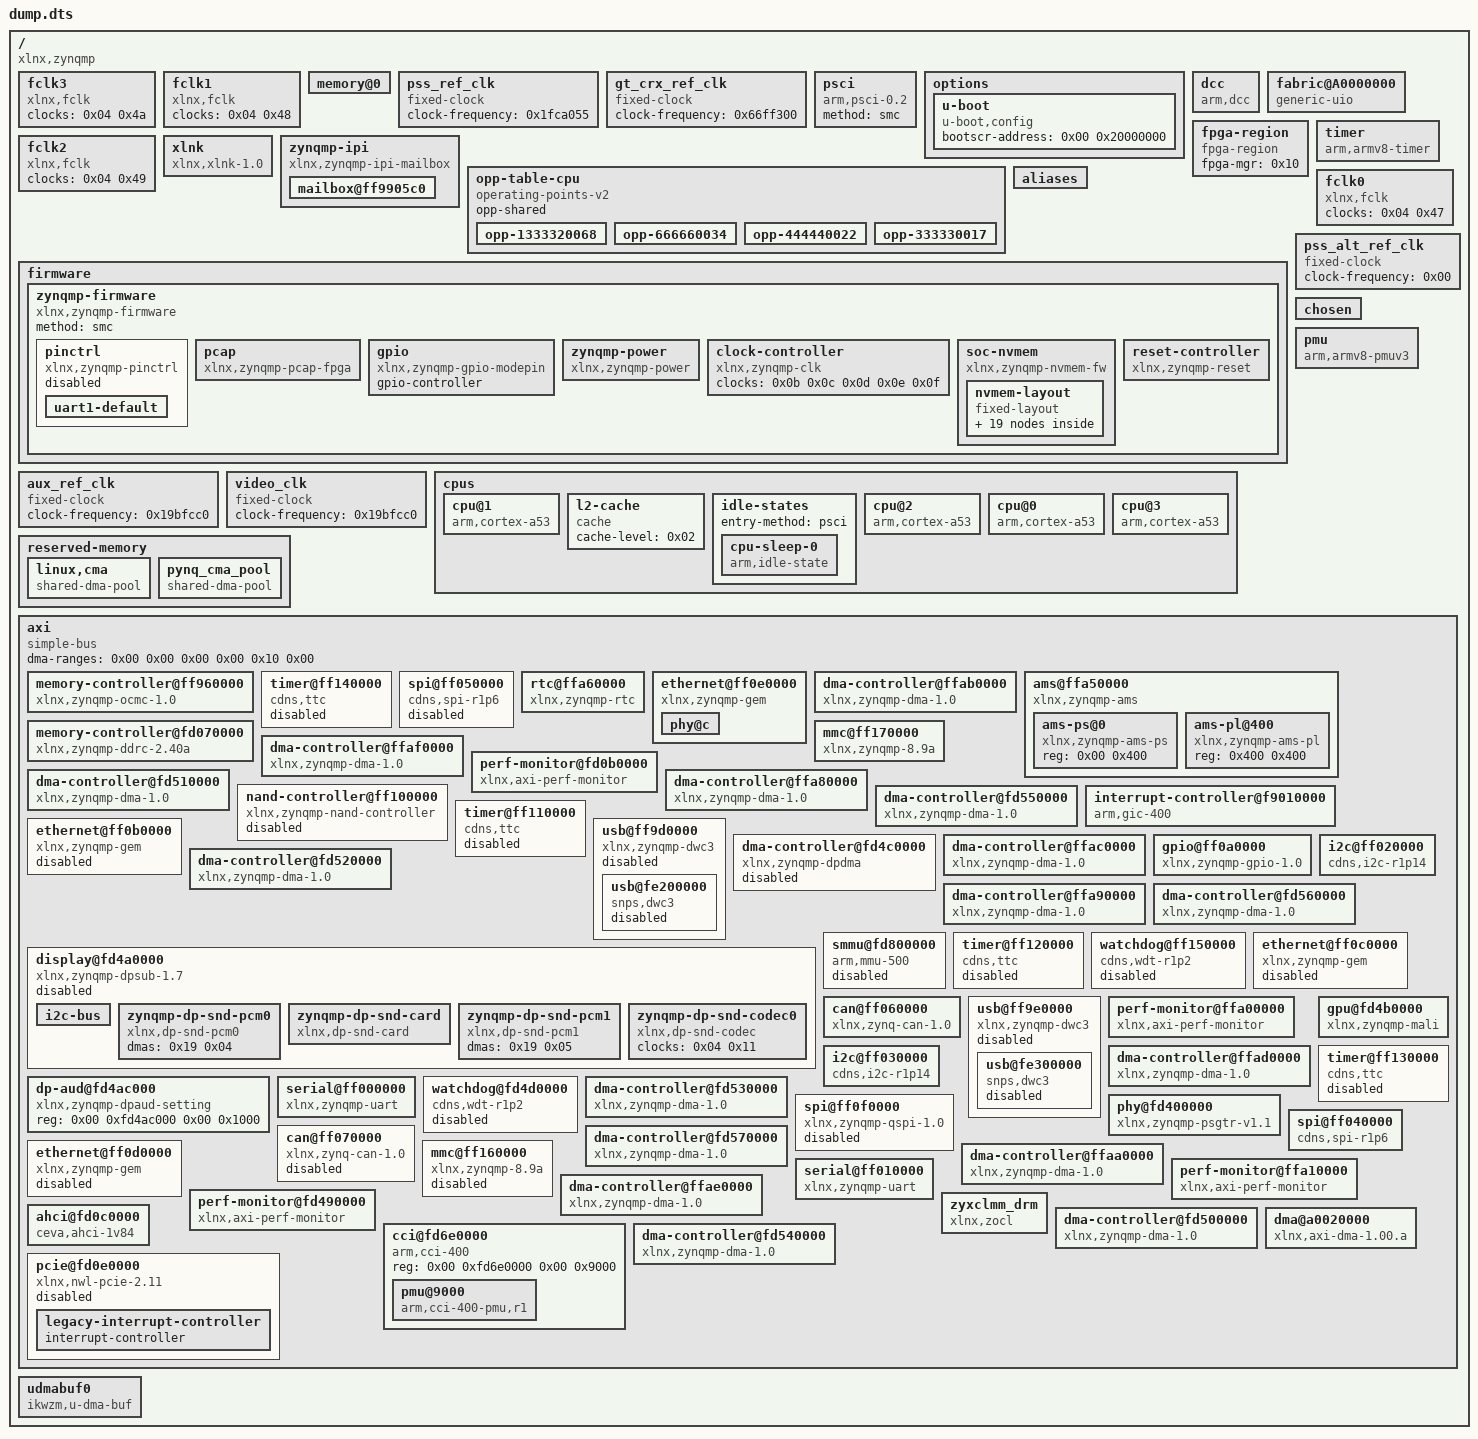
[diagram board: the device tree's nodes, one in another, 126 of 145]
/dts-v1/;

/ {
	#address-cells = <0x02>;
	#size-cells = <0x02>;
	compatible = "xlnx,zynqmp";

	fclk3 {
		clock-names = "fclk3";
		clocks = <0x04 0x4a>;
		compatible = "xlnx,fclk";
		status = "okay";
		phandle = <0x76>;
	};

	fclk1 {
		clock-names = "fclk1";
		clocks = <0x04 0x48>;
		compatible = "xlnx,fclk";
		status = "okay";
		phandle = <0x74>;
	};

	memory@0 {
		device_type = "memory";
		reg = <0x00 0x00 0x00 0x7ff00000 0x08 0x00 0x03 0x80000000>;
	};

	pss_ref_clk {
		bootph-all;
		#clock-cells = <0x00>;
		clock-frequency = <0x1fca055>;
		compatible = "fixed-clock";
		phandle = <0x0b>;
	};

	gt_crx_ref_clk {
		bootph-all;
		#clock-cells = <0x00>;
		clock-frequency = <0x66ff300>;
		compatible = "fixed-clock";
		phandle = <0x0f>;
	};

	psci {
		method = "smc";
		compatible = "arm,psci-0.2";
	};

	options {

		u-boot {
			compatible = "u-boot,config";
			bootscr-address = <0x00 0x20000000>;
		};
	};

	dcc {
		bootph-all;
		compatible = "arm,dcc";
		status = "okay";
		phandle = <0x20>;
	};

	fragment@0 {
		target-path = "/axi";

		__overlay__ {
			#address-cells = <0x02>;
			#size-cells = <0x01>;

			dma@a0020000 {
				dma-coherent;
				compatible = "xlnx,axi-dma-1.00.a";
				status = "okay";
				reg = <0x00 0xa0020000 0x10000>;
				phandle = <0x79>;
			};
		};
	};

	fabric@A0000000 {
		interrupts = <0x00 0x59 0x04>;
		interrupt-parent = <0x05>;
		compatible = "generic-uio";
		reg = <0x00 0xa0000000 0x00 0x10000>;
	};

	fpga-region {
		fpga-mgr = <0x10>;
		#address-cells = <0x02>;
		#size-cells = <0x02>;
		compatible = "fpga-region";
		ranges;
		phandle = <0x36>;
	};

	timer {
		interrupts = <0x01 0x0d 0xf08 0x01 0x0e 0xf08 0x01 0x0b 0xf08 0x01 0x0a 0xf08>;
		interrupt-parent = <0x05>;
		compatible = "arm,armv8-timer";
	};

	fclk2 {
		clock-names = "fclk2";
		clocks = <0x04 0x49>;
		compatible = "xlnx,fclk";
		status = "okay";
		phandle = <0x75>;
	};

	xlnk {
		compatible = "xlnx,xlnk-1.0";
	};

	zynqmp-ipi {
		#address-cells = <0x02>;
		xlnx,ipi-id = <0x00>;
		bootph-all;
		interrupts = <0x00 0x23 0x04>;
		#size-cells = <0x02>;
		interrupt-parent = <0x05>;
		compatible = "xlnx,zynqmp-ipi-mailbox";
		ranges;
		phandle = <0x1f>;

		mailbox@ff9905c0 {
			xlnx,ipi-id = <0x04>;
			reg-names = "local_request_region\0local_response_region\0remote_request_region\0remote_response_region";
			bootph-all;
			#mbox-cells = <0x01>;
			reg = <0x00 0xff9905c0 0x00 0x20 0x00 0xff9905e0 0x00 0x20 0x00 0xff990e80 0x00 0x20 0x00 0xff990ea0 0x00 0x20>;
			phandle = <0x0a>;
		};
	};

	opp-table-cpu {
		opp-shared;
		compatible = "operating-points-v2";
		phandle = <0x01>;

		opp-1333320068 {
			opp-microvolt = <0xf4240>;
			opp-hz = <0x00 0x4f78d984>;
			clock-latency-ns = <0x7a120>;
		};

		opp-666660034 {
			opp-microvolt = <0xf4240>;
			opp-hz = <0x00 0x27bc6cc2>;
			clock-latency-ns = <0x7a120>;
		};

		opp-444440022 {
			opp-microvolt = <0xf4240>;
			opp-hz = <0x00 0x1a7d9dd6>;
			clock-latency-ns = <0x7a120>;
		};

		opp-333330017 {
			opp-microvolt = <0xf4240>;
			opp-hz = <0x00 0x13de3661>;
			clock-latency-ns = <0x7a120>;
		};
	};

	aliases {
		ethernet0 = "/axi/ethernet@ff0e0000";
		i2c1 = "/axi/i2c@ff030000";
		spi0 = "/axi/spi@ff040000";
		serial1 = "/dcc";
		i2c0 = "/axi/i2c@ff020000";
		serial2 = "/axi/serial@ff010000";
		serial0 = "/axi/serial@ff000000";
	};

	firmware {

		zynqmp-firmware {
			method = "smc";
			bootph-all;
			#power-domain-cells = <0x01>;
			compatible = "xlnx,zynqmp-firmware";
			phandle = <0x12>;

			pinctrl {
				compatible = "xlnx,zynqmp-pinctrl";
				status = "disabled";
				phandle = <0x35>;

				uart1-default {
				};
			};

			pcap {
				compatible = "xlnx,zynqmp-pcap-fpga";
				phandle = <0x10>;
			};

			gpio {
				gpio-controller;
				compatible = "xlnx,zynqmp-gpio-modepin";
				phandle = <0x17>;
				#gpio-cells = <0x02>;
			};

			zynqmp-power {
				bootph-all;
				interrupts = <0x00 0x23 0x04>;
				interrupt-parent = <0x05>;
				compatible = "xlnx,zynqmp-power";
				phandle = <0x21>;
				mboxes = <0x0a 0x00 0x0a 0x01>;
				mbox-names = "tx\0rx";
			};

			clock-controller {
				clock-names = "pss_ref_clk\0video_clk\0pss_alt_ref_clk\0aux_ref_clk\0gt_crx_ref_clk";
				bootph-all;
				clocks = <0x0b 0x0c 0x0d 0x0e 0x0f>;
				#clock-cells = <0x01>;
				compatible = "xlnx,zynqmp-clk";
				phandle = <0x04>;
			};

			soc-nvmem {
				compatible = "xlnx,zynqmp-nvmem-fw";

				nvmem-layout {
					#address-cells = <0x01>;
					#size-cells = <0x01>;
					compatible = "fixed-layout";

					efuse-usr3@2c {
						reg = <0x2c 0x04>;
						phandle = <0x27>;
					};

					efuse-pufuser@100 {
						reg = <0x100 0x7f>;
						phandle = <0x34>;
					};

					efuse-ppk1hash@d0 {
						reg = <0xd0 0x30>;
						phandle = <0x33>;
					};

					efuse-sec@58 {
						reg = <0x58 0x04>;
						phandle = <0x2f>;
					};

					efuse-ppk0hash@a0 {
						reg = <0xa0 0x30>;
						phandle = <0x32>;
					};

					efuse-usr1@24 {
						reg = <0x24 0x04>;
						phandle = <0x25>;
					};

					efuse-miscusr@40 {
						reg = <0x40 0x04>;
						phandle = <0x2c>;
					};

					efuse-usr6@38 {
						reg = <0x38 0x04>;
						phandle = <0x2a>;
					};

					efuse-usr4@30 {
						reg = <0x30 0x04>;
						phandle = <0x28>;
					};

					efuse-dna@c {
						reg = <0x0c 0x0c>;
						phandle = <0x23>;
					};

					soc-revision@0 {
						reg = <0x00 0x04>;
						phandle = <0x22>;
					};

					efuse-spkid@5c {
						reg = <0x5c 0x04>;
						phandle = <0x30>;
					};

					efuse-chash@50 {
						reg = <0x50 0x04>;
						phandle = <0x2d>;
					};

					efuse-pufmisc@54 {
						reg = <0x54 0x04>;
						phandle = <0x2e>;
					};

					efuse-usr7@3c {
						reg = <0x3c 0x04>;
						phandle = <0x2b>;
					};

					efuse-usr2@28 {
						reg = <0x28 0x04>;
						phandle = <0x26>;
					};

					efuse-usr0@20 {
						reg = <0x20 0x04>;
						phandle = <0x24>;
					};

					efuse-aeskey@60 {
						reg = <0x60 0x20>;
						phandle = <0x31>;
					};

					efuse-usr5@34 {
						reg = <0x34 0x04>;
						phandle = <0x29>;
					};
				};
			};

			reset-controller {
				#reset-cells = <0x01>;
				compatible = "xlnx,zynqmp-reset";
				phandle = <0x11>;
			};
		};
	};

	fclk0 {
		clock-names = "fclk0";
		clocks = <0x04 0x47>;
		compatible = "xlnx,fclk";
		status = "okay";
		phandle = <0x73>;
	};

	pss_alt_ref_clk {
		bootph-all;
		#clock-cells = <0x00>;
		clock-frequency = <0x00>;
		compatible = "fixed-clock";
		phandle = <0x0d>;
	};

	aux_ref_clk {
		bootph-all;
		#clock-cells = <0x00>;
		clock-frequency = <0x19bfcc0>;
		compatible = "fixed-clock";
		phandle = <0x0e>;
	};

	chosen {
		u-boot,version = "2024.01";
		bootargs = "root=/dev/mmcblk0p2 rw earlyprintk rootfstype=ext4 rootwait devtmpfs.mount=1 uio_pdrv_genirq.of_id=\"generic-uio\" clk_ignore_unused";
		u-boot,bootconf = "conf-1";
		pynq_board = "Pynq-IMPCAS-ZU15";
		stdout-path = "serial0:115200n8";
	};

	video_clk {
		bootph-all;
		#clock-cells = <0x00>;
		clock-frequency = <0x19bfcc0>;
		compatible = "fixed-clock";
		phandle = <0x0c>;
	};

	pmu {
		interrupt-affinity = <0x06 0x07 0x08 0x09>;
		interrupts = <0x00 0x8f 0x04 0x00 0x90 0x04 0x00 0x91 0x04 0x00 0x92 0x04>;
		interrupt-parent = <0x05>;
		compatible = "arm,armv8-pmuv3";
	};

	cpus {
		#address-cells = <0x01>;
		#size-cells = <0x00>;

		cpu@1 {
			cpu-idle-states = <0x02>;
			device_type = "cpu";
			compatible = "arm,cortex-a53";
			next-level-cache = <0x03>;
			reg = <0x01>;
			enable-method = "psci";
			phandle = <0x07>;
			operating-points-v2 = <0x01>;
		};

		l2-cache {
			cache-level = <0x02>;
			compatible = "cache";
			phandle = <0x03>;
		};

		idle-states {
			entry-method = "psci";

			cpu-sleep-0 {
				entry-latency-us = <0x12c>;
				local-timer-stop;
				exit-latency-us = <0x258>;
				arm,psci-suspend-param = <0x40000000>;
				compatible = "arm,idle-state";
				phandle = <0x02>;
				min-residency-us = <0x2710>;
			};
		};

		cpu@2 {
			cpu-idle-states = <0x02>;
			device_type = "cpu";
			compatible = "arm,cortex-a53";
			next-level-cache = <0x03>;
			reg = <0x02>;
			enable-method = "psci";
			phandle = <0x08>;
			operating-points-v2 = <0x01>;
		};

		cpu@0 {
			clocks = <0x04 0x0a>;
			cpu-idle-states = <0x02>;
			device_type = "cpu";
			compatible = "arm,cortex-a53";
			next-level-cache = <0x03>;
			reg = <0x00>;
			enable-method = "psci";
			phandle = <0x06>;
			operating-points-v2 = <0x01>;
		};

		cpu@3 {
			cpu-idle-states = <0x02>;
			device_type = "cpu";
			compatible = "arm,cortex-a53";
			next-level-cache = <0x03>;
			reg = <0x03>;
			enable-method = "psci";
			phandle = <0x09>;
			operating-points-v2 = <0x01>;
		};
	};

	__symbols__ {
		axi_dma_coherent = "/fragment@0/__overlay__/dma@a0020000";
		efuse_usr0 = "/firmware/zynqmp-firmware/soc-nvmem/nvmem-layout/efuse-usr0@20";
		fpd_dma_chan3 = "/axi/dma-controller@fd520000";
		efuse_ppk0hash = "/firmware/zynqmp-firmware/soc-nvmem/nvmem-layout/efuse-ppk0hash@a0";
		ams_ps = "/axi/ams@ffa50000/ams-ps@0";
		nand0 = "/axi/nand-controller@ff100000";
		fclk3 = "/fclk3";
		zynqmp_pcap = "/firmware/zynqmp-firmware/pcap";
		CPU_SLEEP_0 = "/cpus/idle-states/cpu-sleep-0";
		phyc = "/axi/ethernet@ff0e0000/phy@c";
		efuse_chash = "/firmware/zynqmp-firmware/soc-nvmem/nvmem-layout/efuse-chash@50";
		ipi_mailbox_pmu1 = "/zynqmp-ipi/mailbox@ff9905c0";
		i2c1 = "/axi/i2c@ff030000";
		fpd_dma_chan1 = "/axi/dma-controller@fd500000";
		efuse_sec = "/firmware/zynqmp-firmware/soc-nvmem/nvmem-layout/efuse-sec@58";
		ttc3 = "/axi/timer@ff140000";
		qspi = "/axi/spi@ff0f0000";
		zynqmp_dp_snd_pcm0 = "/axi/display@fd4a0000/zynqmp-dp-snd-pcm0";
		fclk1 = "/fclk1";
		gpu = "/axi/gpu@fd4b0000";
		spi0 = "/axi/spi@ff040000";
		lpd_dma_chan8 = "/axi/dma-controller@ffaf0000";
		efuse_usr7 = "/firmware/zynqmp-firmware/soc-nvmem/nvmem-layout/efuse-usr7@3c";
		gpio = "/axi/gpio@ff0a0000";
		zynqmp_clk = "/firmware/zynqmp-firmware/clock-controller";
		usb1 = "/axi/usb@ff9e0000";
		ttc1 = "/axi/timer@ff120000";
		amba = "/axi";
		efuse_spkid = "/firmware/zynqmp-firmware/soc-nvmem/nvmem-layout/efuse-spkid@5c";
		pss_ref_clk = "/pss_ref_clk";
		lpd_dma_chan6 = "/axi/dma-controller@ffad0000";
		efuse_usr5 = "/firmware/zynqmp-firmware/soc-nvmem/nvmem-layout/efuse-usr5@34";
		fpd_dma_chan8 = "/axi/dma-controller@fd570000";
		efuse_ppk1hash = "/firmware/zynqmp-firmware/soc-nvmem/nvmem-layout/efuse-ppk1hash@d0";
		gem3 = "/axi/ethernet@ff0e0000";
		cpu3 = "/cpus/cpu@3";
		zynqmp_dpaud_setting = "/axi/dp-aud@fd4ac000";
		dwc3_0 = "/axi/usb@ff9d0000/usb@fe200000";
		perf_monitor_cci = "/axi/perf-monitor@fd490000";
		lpd_dma_chan4 = "/axi/dma-controller@ffab0000";
		efuse_usr3 = "/firmware/zynqmp-firmware/soc-nvmem/nvmem-layout/efuse-usr3@2c";
		fpd_dma_chan6 = "/axi/dma-controller@fd550000";
		efuse_aeskey = "/firmware/zynqmp-firmware/soc-nvmem/nvmem-layout/efuse-aeskey@60";
		gt_crx_ref_clk = "/gt_crx_ref_clk";
		gic = "/axi/interrupt-controller@f9010000";
		gem1 = "/axi/ethernet@ff0c0000";
		sata = "/axi/ahci@fd0c0000";
		cpu1 = "/cpus/cpu@1";
		xilinx_ams = "/axi/ams@ffa50000";
		perf_monitor_lpd = "/axi/perf-monitor@ffa10000";
		uart0 = "/axi/serial@ff000000";
		zynqmp_dp_snd_codec0 = "/axi/display@fd4a0000/zynqmp-dp-snd-codec0";
		dcc = "/dcc";
		lpd_dma_chan2 = "/axi/dma-controller@ffa90000";
		ams_pl = "/axi/ams@ffa50000/ams-pl@400";
		L2 = "/cpus/l2-cache";
		efuse_usr1 = "/firmware/zynqmp-firmware/soc-nvmem/nvmem-layout/efuse-usr1@24";
		fpd_dma_chan4 = "/axi/dma-controller@fd530000";
		cci = "/axi/cci@fd6e0000";
		perf_monitor_ddr = "/axi/perf-monitor@fd0b0000";
		cpu_opp_table = "/opp-table-cpu";
		can0 = "/axi/can@ff060000";
		pcie = "/axi/pcie@fd0e0000";
		sdhci0 = "/axi/mmc@ff160000";
		perf_monitor_ocm = "/axi/perf-monitor@ffa00000";
		watchdog0 = "/axi/watchdog@fd4d0000";
		fpga_full = "/fpga-region";
		fpd_dma_chan2 = "/axi/dma-controller@fd510000";
		zynqmp_firmware = "/firmware/zynqmp-firmware";
		zynqmp_dp_snd_pcm1 = "/axi/display@fd4a0000/zynqmp-dp-snd-pcm1";
		fclk2 = "/fclk2";
		spi1 = "/axi/spi@ff050000";
		sys_cma = "/reserved-memory/linux,cma";
		ocm = "/axi/memory-controller@ff960000";
		i2c0 = "/axi/i2c@ff020000";
		ttc2 = "/axi/timer@ff130000";
		soc_revision = "/firmware/zynqmp-firmware/soc-nvmem/nvmem-layout/soc-revision@0";
		fclk0 = "/fclk0";
		pss_alt_ref_clk = "/pss_alt_ref_clk";
		lpd_dma_chan7 = "/axi/dma-controller@ffae0000";
		efuse_usr6 = "/firmware/zynqmp-firmware/soc-nvmem/nvmem-layout/efuse-usr6@38";
		efuse_dna = "/firmware/zynqmp-firmware/soc-nvmem/nvmem-layout/efuse-dna@c";
		aux_ref_clk = "/aux_ref_clk";
		psgtr = "/axi/phy@fd400000";
		usb0 = "/axi/usb@ff9d0000";
		ttc0 = "/axi/timer@ff110000";
		efuse_pufuser = "/firmware/zynqmp-firmware/soc-nvmem/nvmem-layout/efuse-pufuser@100";
		mc = "/axi/memory-controller@fd070000";
		zynqmp_dpsub = "/axi/display@fd4a0000";
		pinctrl0 = "/firmware/zynqmp-firmware/pinctrl";
		dwc3_1 = "/axi/usb@ff9e0000/usb@fe300000";
		lpd_dma_chan5 = "/axi/dma-controller@ffac0000";
		zynqmp_ipi = "/zynqmp-ipi";
		efuse_usr4 = "/firmware/zynqmp-firmware/soc-nvmem/nvmem-layout/efuse-usr4@30";
		fpd_dma_chan7 = "/axi/dma-controller@fd560000";
		video_clk = "/video_clk";
		gem2 = "/axi/ethernet@ff0d0000";
		efuse_pufmisc = "/firmware/zynqmp-firmware/soc-nvmem/nvmem-layout/efuse-pufmisc@54";
		zynqmp_dpdma = "/axi/dma-controller@fd4c0000";
		cpu2 = "/cpus/cpu@2";
		uart1 = "/axi/serial@ff010000";
		efuse_miscusr = "/firmware/zynqmp-firmware/soc-nvmem/nvmem-layout/efuse-miscusr@40";
		lpd_dma_chan3 = "/axi/dma-controller@ffaa0000";
		efuse_usr2 = "/firmware/zynqmp-firmware/soc-nvmem/nvmem-layout/efuse-usr2@28";
		fpd_dma_chan5 = "/axi/dma-controller@fd540000";
		zynqmp_dp_snd_card0 = "/axi/display@fd4a0000/zynqmp-dp-snd-card";
		zynqmp_power = "/firmware/zynqmp-firmware/zynqmp-power";
		can1 = "/axi/can@ff070000";
		gem0 = "/axi/ethernet@ff0b0000";
		udmabuf0 = "/udmabuf0";
		pcie_intc = "/axi/pcie@fd0e0000/legacy-interrupt-controller";
		sdhci1 = "/axi/mmc@ff170000";
		rtc = "/axi/rtc@ffa60000";
		smmu = "/axi/smmu@fd800000";
		pynq_cma_pool = "/reserved-memory/pynq_cma_pool";
		lpd_watchdog = "/axi/watchdog@ff150000";
		modepin_gpio = "/firmware/zynqmp-firmware/gpio";
		cpu0 = "/cpus/cpu@0";
		zynqmp_reset = "/firmware/zynqmp-firmware/reset-controller";
		lpd_dma_chan1 = "/axi/dma-controller@ffa80000";
	};

	reserved-memory {
		#address-cells = <0x02>;
		#size-cells = <0x02>;
		ranges;

		linux,cma {
			linux,cma-default;
			alloc-ranges = <0x00 0x20000000 0x00 0x60000000>;
			compatible = "shared-dma-pool";
			size = <0x00 0x10000000>;
			phandle = <0x1d>;
			reusable;
		};

		pynq_cma_pool {
			alloc-ranges = <0x08 0x00 0x02 0x00>;
			compatible = "shared-dma-pool";
			size = <0x01 0x00>;
			phandle = <0x1e>;
			reusable;
		};
	};

	axi {
		dma-ranges = <0x00 0x00 0x00 0x00 0x10 0x00>;
		#address-cells = <0x02>;
		bootph-all;
		#size-cells = <0x02>;
		compatible = "simple-bus";
		ranges;
		phandle = <0x37>;

		memory-controller@ff960000 {
			interrupts = <0x00 0x0a 0x04>;
			interrupt-parent = <0x05>;
			compatible = "xlnx,zynqmp-ocmc-1.0";
			reg = <0x00 0xff960000 0x00 0x1000>;
			phandle = <0x55>;
		};

		timer@ff140000 {
			power-domains = <0x12 0x1b>;
			timer-width = <0x20>;
			interrupts = <0x00 0x2d 0x04 0x00 0x2e 0x04 0x00 0x2f 0x04>;
			clocks = <0x04 0x1f>;
			interrupt-parent = <0x05>;
			compatible = "cdns,ttc";
			status = "disabled";
			reg = <0x00 0xff140000 0x00 0x1000>;
			phandle = <0x65>;
		};

		spi@ff050000 {
			power-domains = <0x12 0x24>;
			#address-cells = <0x01>;
			clock-names = "ref_clk\0pclk";
			interrupts = <0x00 0x14 0x04>;
			clocks = <0x04 0x3b 0x04 0x1f>;
			#size-cells = <0x00>;
			interrupt-parent = <0x05>;
			compatible = "cdns,spi-r1p6";
			status = "disabled";
			reg = <0x00 0xff050000 0x00 0x1000>;
			phandle = <0x61>;
		};

		rtc@ffa60000 {
			calibration = <0x7fff>;
			interrupts = <0x00 0x1a 0x04 0x00 0x1b 0x04>;
			interrupt-parent = <0x05>;
			compatible = "xlnx,zynqmp-rtc";
			status = "okay";
			interrupt-names = "alarm\0sec";
			reg = <0x00 0xffa60000 0x00 0x100>;
			phandle = <0x5c>;
		};

		ethernet@ff0e0000 {
			power-domains = <0x12 0x20>;
			iommus = <0x13 0x877>;
			#address-cells = <0x01>;
			phy-mode = "rgmii-id";
			clock-names = "pclk\0hclk\0tx_clk\0rx_clk\0tsu_clk";
			assigned-clocks = <0x04 0x2c>;
			local-mac-address = [8a c7 1e ff 92 3f];
			resets = <0x11 0x20>;
			interrupts = <0x00 0x3f 0x04 0x00 0x3f 0x04>;
			clocks = <0x04 0x1f 0x04 0x6b 0x04 0x30 0x04 0x34 0x04 0x2c>;
			#size-cells = <0x00>;
			interrupt-parent = <0x05>;
			compatible = "xlnx,zynqmp-gem\0cdns,gem";
			status = "okay";
			reg = <0x00 0xff0e0000 0x00 0x1000>;
			phandle = <0x51>;
			phy-handle = <0x14>;
			reset-names = "gem3_rst";
			xlnx,ptp-enet-clock = <0x00>;

			phy@c {
				ti,dp83867-rxctrl-strap-quirk;
				ti,tx-internal-delay = <0x0a>;
				ti,fifo-depth = <0x01>;
				ti,rx-internal-delay = <0x08>;
				reg = <0x0c>;
				phandle = <0x14>;
			};
		};

		dma-controller@ffab0000 {
			power-domains = <0x12 0x2b>;
			clock-names = "clk_main\0clk_apb";
			interrupts = <0x00 0x50 0x04>;
			clocks = <0x04 0x44 0x04 0x1f>;
			interrupt-parent = <0x05>;
			xlnx,bus-width = <0x40>;
			compatible = "xlnx,zynqmp-dma-1.0";
			status = "okay";
			reg = <0x00 0xffab0000 0x00 0x1000>;
			phandle = <0x47>;
			#dma-cells = <0x01>;
		};

		ams@ffa50000 {
			#address-cells = <0x01>;
			interrupts = <0x00 0x38 0x04>;
			clocks = <0x04 0x46>;
			#io-channel-cells = <0x01>;
			#size-cells = <0x01>;
			interrupt-parent = <0x05>;
			compatible = "xlnx,zynqmp-ams";
			ranges = <0x00 0x00 0xffa50800 0x800>;
			status = "okay";
			reg = <0x00 0xffa50000 0x00 0x800>;
			phandle = <0x6e>;

			ams-ps@0 {
				compatible = "xlnx,zynqmp-ams-ps";
				status = "okay";
				reg = <0x00 0x400>;
				phandle = <0x6f>;
			};

			ams-pl@400 {
				compatible = "xlnx,zynqmp-ams-pl";
				status = "okay";
				reg = <0x400 0x400>;
				phandle = <0x70>;
			};
		};

		memory-controller@fd070000 {
			interrupts = <0x00 0x70 0x04>;
			interrupt-parent = <0x05>;
			compatible = "xlnx,zynqmp-ddrc-2.40a";
			reg = <0x00 0xfd070000 0x00 0x30000>;
			phandle = <0x4c>;
		};

		mmc@ff170000 {
			power-domains = <0x12 0x28>;
			iommus = <0x13 0x871>;
			clock-output-names = "clk_out_sd1\0clk_in_sd1";
			xlnx,mio-bank = <0x01>;
			clock-names = "clk_xin\0clk_ahb";
			assigned-clocks = <0x04 0x37>;
			bootph-all;
			resets = <0x11 0x27>;
			interrupts = <0x00 0x31 0x04>;
			clocks = <0x04 0x37 0x04 0x1f>;
			#clock-cells = <0x01>;
			interrupt-parent = <0x05>;
			clock-frequency = <0xbebba31>;
			no-1-8-v;
			compatible = "xlnx,zynqmp-8.9a\0arasan,sdhci-8.9a";
			status = "okay";
			disable-wp;
			reg = <0x00 0xff170000 0x00 0x1000>;
			phandle = <0x5f>;
			disable-cd;
		};

		dma-controller@ffaf0000 {
			power-domains = <0x12 0x2b>;
			clock-names = "clk_main\0clk_apb";
			interrupts = <0x00 0x54 0x04>;
			clocks = <0x04 0x44 0x04 0x1f>;
			interrupt-parent = <0x05>;
			xlnx,bus-width = <0x40>;
			compatible = "xlnx,zynqmp-dma-1.0";
			status = "okay";
			reg = <0x00 0xffaf0000 0x00 0x1000>;
			phandle = <0x4b>;
			#dma-cells = <0x01>;
		};

		perf-monitor@fd0b0000 {
			xlnx,metric-count-width = <0x20>;
			xlnx,have-sampled-metric-cnt = <0x01>;
			xlnx,enable-trace = <0x00>;
			xlnx,global-count-width = <0x20>;
			xlnx,enable-event-count = <0x01>;
			interrupts = <0x00 0x7b 0x04>;
			clocks = <0x04 0x1c>;
			xlnx,enable-profile = <0x00>;
			xlnx,metric-count-scale = <0x01>;
			interrupt-parent = <0x05>;
			xlnx,num-monitor-slots = <0x06>;
			compatible = "xlnx,axi-perf-monitor";
			xlnx,num-of-counters = <0x0a>;
			reg = <0x00 0xfd0b0000 0x00 0x10000>;
			phandle = <0x57>;
			xlnx,metrics-sample-count-width = <0x20>;
			xlnx,enable-event-log = <0x00>;
		};

		dma-controller@fd510000 {
			power-domains = <0x12 0x2a>;
			iommus = <0x13 0x14e9>;
			clock-names = "clk_main\0clk_apb";
			interrupts = <0x00 0x7d 0x04>;
			clocks = <0x04 0x13 0x04 0x1f>;
			interrupt-parent = <0x05>;
			xlnx,bus-width = <0x80>;
			compatible = "xlnx,zynqmp-dma-1.0";
			status = "okay";
			reg = <0x00 0xfd510000 0x00 0x1000>;
			phandle = <0x3c>;
			#dma-cells = <0x01>;
		};

		dma-controller@ffa80000 {
			power-domains = <0x12 0x2b>;
			clock-names = "clk_main\0clk_apb";
			interrupts = <0x00 0x4d 0x04>;
			clocks = <0x04 0x44 0x04 0x1f>;
			interrupt-parent = <0x05>;
			xlnx,bus-width = <0x40>;
			compatible = "xlnx,zynqmp-dma-1.0";
			status = "okay";
			reg = <0x00 0xffa80000 0x00 0x1000>;
			phandle = <0x44>;
			#dma-cells = <0x01>;
		};

		nand-controller@ff100000 {
			power-domains = <0x12 0x2c>;
			iommus = <0x13 0x872>;
			#address-cells = <0x01>;
			clock-names = "controller\0bus";
			interrupts = <0x00 0x0e 0x04>;
			clocks = <0x04 0x3c 0x04 0x1f>;
			#size-cells = <0x00>;
			interrupt-parent = <0x05>;
			compatible = "xlnx,zynqmp-nand-controller\0arasan,nfc-v3p10";
			status = "disabled";
			reg = <0x00 0xff100000 0x00 0x1000>;
			phandle = <0x4d>;
		};

		dma-controller@fd550000 {
			power-domains = <0x12 0x2a>;
			iommus = <0x13 0x14ed>;
			clock-names = "clk_main\0clk_apb";
			interrupts = <0x00 0x81 0x04>;
			clocks = <0x04 0x13 0x04 0x1f>;
			interrupt-parent = <0x05>;
			xlnx,bus-width = <0x80>;
			compatible = "xlnx,zynqmp-dma-1.0";
			status = "okay";
			reg = <0x00 0xfd550000 0x00 0x1000>;
			phandle = <0x40>;
			#dma-cells = <0x01>;
		};

		interrupt-controller@f9010000 {
			num_cpus = <0x02>;
			interrupts = <0x01 0x09 0xf04>;
			interrupt-parent = <0x05>;
			compatible = "arm,gic-400";
			#interrupt-cells = <0x03>;
			num_interrupts = <0x60>;
			reg = <0x00 0xf9010000 0x00 0x10000 0x00 0xf9020000 0x00 0x20000 0x00 0xf9040000 0x00 0x20000 0x00 0xf9060000 0x00 0x20000>;
			phandle = <0x05>;
			interrupt-controller;
		};

		timer@ff110000 {
			power-domains = <0x12 0x18>;
			timer-width = <0x20>;
			interrupts = <0x00 0x24 0x04 0x00 0x25 0x04 0x00 0x26 0x04>;
			clocks = <0x04 0x1f>;
			interrupt-parent = <0x05>;
			compatible = "cdns,ttc";
			status = "disabled";
			reg = <0x00 0xff110000 0x00 0x1000>;
			phandle = <0x62>;
		};

		ethernet@ff0b0000 {
			power-domains = <0x12 0x1d>;
			iommus = <0x13 0x874>;
			#address-cells = <0x01>;
			clock-names = "pclk\0hclk\0tx_clk\0rx_clk\0tsu_clk";
			assigned-clocks = <0x04 0x2c>;
			resets = <0x11 0x1d>;
			interrupts = <0x00 0x39 0x04 0x00 0x39 0x04>;
			clocks = <0x04 0x1f 0x04 0x68 0x04 0x2d 0x04 0x31 0x04 0x2c>;
			#size-cells = <0x00>;
			interrupt-parent = <0x05>;
			compatible = "xlnx,zynqmp-gem\0cdns,gem";
			status = "disabled";
			reg = <0x00 0xff0b0000 0x00 0x1000>;
			phandle = <0x4e>;
			reset-names = "gem0_rst";
		};

		usb@ff9d0000 {
			power-domains = <0x12 0x16>;
			#address-cells = <0x02>;
			clock-names = "bus_clk\0ref_clk";
			assigned-clocks = <0x04 0x20 0x04 0x22>;
			resets = <0x11 0x3b 0x11 0x3d 0x11 0x3f>;
			clocks = <0x04 0x20 0x04 0x22>;
			#size-cells = <0x02>;
			reset-gpios = <0x17 0x01 0x01>;
			compatible = "xlnx,zynqmp-dwc3";
			ranges;
			status = "disabled";
			reg = <0x00 0xff9d0000 0x00 0x100>;
			phandle = <0x68>;
			reset-names = "usb_crst\0usb_hibrst\0usb_apbrst";

			usb@fe200000 {
				iommus = <0x13 0x860>;
				snps,resume-hs-terminations;
				snps,quirk-frame-length-adjustment = <0x20>;
				clock-names = "ref";
				interrupts = <0x00 0x41 0x04 0x00 0x41 0x04 0x00 0x45 0x04 0x00 0x4b 0x04>;
				clocks = <0x04 0x22>;
				interrupt-parent = <0x05>;
				compatible = "snps,dwc3";
				status = "disabled";
				interrupt-names = "host\0peripheral\0otg\0wakeup";
				reg = <0x00 0xfe200000 0x00 0x40000>;
				phandle = <0x69>;
			};
		};

		dma-controller@fd4c0000 {
			power-domains = <0x12 0x29>;
			iommus = <0x13 0xce4>;
			clock-names = "axi_clk";
			assigned-clocks = <0x04 0x14>;
			interrupts = <0x00 0x7a 0x04>;
			clocks = <0x04 0x14>;
			interrupt-parent = <0x05>;
			compatible = "xlnx,zynqmp-dpdma";
			status = "disabled";
			reg = <0x00 0xfd4c0000 0x00 0x1000>;
			phandle = <0x19>;
			dma-channels = <0x06>;
			#dma-cells = <0x01>;
		};

		dma-controller@ffac0000 {
			power-domains = <0x12 0x2b>;
			clock-names = "clk_main\0clk_apb";
			interrupts = <0x00 0x51 0x04>;
			clocks = <0x04 0x44 0x04 0x1f>;
			interrupt-parent = <0x05>;
			xlnx,bus-width = <0x40>;
			compatible = "xlnx,zynqmp-dma-1.0";
			status = "okay";
			reg = <0x00 0xffac0000 0x00 0x1000>;
			phandle = <0x48>;
			#dma-cells = <0x01>;
		};

		gpio@ff0a0000 {
			power-domains = <0x12 0x2e>;
			gpio-mask-low = <0x5600>;
			gpio-controller;
			interrupts = <0x00 0x10 0x04>;
			clocks = <0x04 0x1f>;
			gpio-mask-high = <0x00>;
			interrupt-parent = <0x05>;
			compatible = "xlnx,zynqmp-gpio-1.0";
			#interrupt-cells = <0x02>;
			status = "okay";
			reg = <0x00 0xff0a0000 0x00 0x1000>;
			phandle = <0x52>;
			emio-gpio-width = <0x20>;
			#gpio-cells = <0x02>;
			interrupt-controller;
		};

		i2c@ff020000 {
			power-domains = <0x12 0x25>;
			#address-cells = <0x01>;
			interrupts = <0x00 0x11 0x04>;
			clocks = <0x04 0x3d>;
			#size-cells = <0x00>;
			interrupt-parent = <0x05>;
			clock-frequency = <0x61a80>;
			compatible = "cdns,i2c-r1p14";
			status = "okay";
			reg = <0x00 0xff020000 0x00 0x1000>;
			phandle = <0x53>;
		};

		dma-controller@fd520000 {
			power-domains = <0x12 0x2a>;
			iommus = <0x13 0x14ea>;
			clock-names = "clk_main\0clk_apb";
			interrupts = <0x00 0x7e 0x04>;
			clocks = <0x04 0x13 0x04 0x1f>;
			interrupt-parent = <0x05>;
			xlnx,bus-width = <0x80>;
			compatible = "xlnx,zynqmp-dma-1.0";
			status = "okay";
			reg = <0x00 0xfd520000 0x00 0x1000>;
			phandle = <0x3d>;
			#dma-cells = <0x01>;
		};

		display@fd4a0000 {
			power-domains = <0x12 0x29>;
			iommus = <0x13 0xce3>;
			clock-names = "dp_apb_clk\0dp_aud_clk\0dp_vtc_pixel_clk_in";
			reg-names = "dp\0blend\0av_buf";
			assigned-clocks = <0x04 0x12 0x04 0x11 0x04 0x10>;
			bootph-all;
			resets = <0x11 0x03>;
			interrupts = <0x00 0x77 0x04>;
			clocks = <0x04 0x1c 0x04 0x11 0x04 0x10>;
			interrupt-parent = <0x05>;
			dma-names = "vid0\0vid1\0vid2\0gfx0";
			compatible = "xlnx,zynqmp-dpsub-1.7";
			status = "disabled";
			xlnx,dpaud-reg = <0x18>;
			reg = <0x00 0xfd4a0000 0x00 0x1000 0x00 0xfd4aa000 0x00 0x1000 0x00 0xfd4ab000 0x00 0x1000>;
			phandle = <0x71>;
			dmas = <0x19 0x00 0x19 0x01 0x19 0x02 0x19 0x03>;

			i2c-bus {
			};

			zynqmp-dp-snd-pcm0 {
				dma-names = "tx";
				compatible = "xlnx,dp-snd-pcm0";
				phandle = <0x1a>;
				dmas = <0x19 0x04>;
			};

			zynqmp-dp-snd-card {
				xlnx,dp-snd-pcm = <0x1a 0x1b>;
				xlnx,dp-snd-codec = <0x1c>;
				compatible = "xlnx,dp-snd-card";
				phandle = <0x72>;
			};

			zynqmp-dp-snd-pcm1 {
				dma-names = "tx";
				compatible = "xlnx,dp-snd-pcm1";
				phandle = <0x1b>;
				dmas = <0x19 0x05>;
			};

			zynqmp-dp-snd-codec0 {
				clock-names = "aud_clk";
				clocks = <0x04 0x11>;
				compatible = "xlnx,dp-snd-codec";
				phandle = <0x1c>;
			};
		};

		dma-controller@ffa90000 {
			power-domains = <0x12 0x2b>;
			clock-names = "clk_main\0clk_apb";
			interrupts = <0x00 0x4e 0x04>;
			clocks = <0x04 0x44 0x04 0x1f>;
			interrupt-parent = <0x05>;
			xlnx,bus-width = <0x40>;
			compatible = "xlnx,zynqmp-dma-1.0";
			status = "okay";
			reg = <0x00 0xffa90000 0x00 0x1000>;
			phandle = <0x45>;
			#dma-cells = <0x01>;
		};

		dma-controller@fd560000 {
			power-domains = <0x12 0x2a>;
			iommus = <0x13 0x14ee>;
			clock-names = "clk_main\0clk_apb";
			interrupts = <0x00 0x82 0x04>;
			clocks = <0x04 0x13 0x04 0x1f>;
			interrupt-parent = <0x05>;
			xlnx,bus-width = <0x80>;
			compatible = "xlnx,zynqmp-dma-1.0";
			status = "okay";
			reg = <0x00 0xfd560000 0x00 0x1000>;
			phandle = <0x41>;
			#dma-cells = <0x01>;
		};

		smmu@fd800000 {
			#global-interrupts = <0x01>;
			interrupts = <0x00 0x9b 0x04 0x00 0x9b 0x04 0x00 0x9b 0x04 0x00 0x9b 0x04 0x00 0x9b 0x04 0x00 0x9b 0x04 0x00 0x9b 0x04 0x00 0x9b 0x04 0x00 0x9b 0x04 0x00 0x9b 0x04 0x00 0x9b 0x04 0x00 0x9b 0x04 0x00 0x9b 0x04 0x00 0x9b 0x04 0x00 0x9b 0x04 0x00 0x9b 0x04 0x00 0x9b 0x04>;
			interrupt-parent = <0x05>;
			#iommu-cells = <0x01>;
			compatible = "arm,mmu-500";
			status = "disabled";
			reg = <0x00 0xfd800000 0x00 0x20000>;
			phandle = <0x13>;
		};

		timer@ff120000 {
			power-domains = <0x12 0x19>;
			timer-width = <0x20>;
			interrupts = <0x00 0x27 0x04 0x00 0x28 0x04 0x00 0x29 0x04>;
			clocks = <0x04 0x1f>;
			interrupt-parent = <0x05>;
			compatible = "cdns,ttc";
			status = "disabled";
			reg = <0x00 0xff120000 0x00 0x1000>;
			phandle = <0x63>;
		};

		watchdog@ff150000 {
			interrupts = <0x00 0x34 0x01>;
			clocks = <0x04 0x70>;
			interrupt-parent = <0x05>;
			timeout-sec = <0x0a>;
			compatible = "cdns,wdt-r1p2";
			status = "disabled";
			reg = <0x00 0xff150000 0x00 0x1000>;
			phandle = <0x6d>;
		};

		ethernet@ff0c0000 {
			power-domains = <0x12 0x1e>;
			iommus = <0x13 0x875>;
			#address-cells = <0x01>;
			clock-names = "pclk\0hclk\0tx_clk\0rx_clk\0tsu_clk";
			assigned-clocks = <0x04 0x2c>;
			resets = <0x11 0x1e>;
			interrupts = <0x00 0x3b 0x04 0x00 0x3b 0x04>;
			clocks = <0x04 0x1f 0x04 0x69 0x04 0x2e 0x04 0x32 0x04 0x2c>;
			#size-cells = <0x00>;
			interrupt-parent = <0x05>;
			compatible = "xlnx,zynqmp-gem\0cdns,gem";
			status = "disabled";
			reg = <0x00 0xff0c0000 0x00 0x1000>;
			phandle = <0x4f>;
			reset-names = "gem1_rst";
		};

		can@ff060000 {
			power-domains = <0x12 0x2f>;
			clock-names = "can_clk\0pclk";
			resets = <0x11 0x28>;
			interrupts = <0x00 0x17 0x04>;
			clocks = <0x04 0x3f 0x04 0x1f>;
			interrupt-parent = <0x05>;
			compatible = "xlnx,zynq-can-1.0";
			status = "okay";
			tx-fifo-depth = <0x40>;
			rx-fifo-depth = <0x40>;
			reg = <0x00 0xff060000 0x00 0x1000>;
			phandle = <0x38>;
		};

		usb@ff9e0000 {
			power-domains = <0x12 0x17>;
			#address-cells = <0x02>;
			clock-names = "bus_clk\0ref_clk";
			assigned-clocks = <0x04 0x21 0x04 0x22>;
			resets = <0x11 0x3c 0x11 0x3e 0x11 0x40>;
			clocks = <0x04 0x21 0x04 0x22>;
			#size-cells = <0x02>;
			compatible = "xlnx,zynqmp-dwc3";
			ranges;
			status = "disabled";
			reg = <0x00 0xff9e0000 0x00 0x100>;
			phandle = <0x6a>;
			reset-names = "usb_crst\0usb_hibrst\0usb_apbrst";

			usb@fe300000 {
				iommus = <0x13 0x861>;
				snps,resume-hs-terminations;
				snps,quirk-frame-length-adjustment = <0x20>;
				clock-names = "ref";
				interrupts = <0x00 0x46 0x04 0x00 0x46 0x04 0x00 0x4a 0x04 0x00 0x4c 0x04>;
				clocks = <0x04 0x22>;
				interrupt-parent = <0x05>;
				compatible = "snps,dwc3";
				status = "disabled";
				interrupt-names = "host\0peripheral\0otg\0wakeup";
				reg = <0x00 0xfe300000 0x00 0x40000>;
				phandle = <0x6b>;
			};
		};

		perf-monitor@ffa00000 {
			xlnx,metric-count-width = <0x20>;
			xlnx,have-sampled-metric-cnt = <0x01>;
			xlnx,enable-trace = <0x00>;
			xlnx,global-count-width = <0x20>;
			xlnx,enable-event-count = <0x01>;
			interrupts = <0x00 0x19 0x04>;
			clocks = <0x04 0x1f>;
			xlnx,enable-profile = <0x00>;
			xlnx,metric-count-scale = <0x01>;
			interrupt-parent = <0x05>;
			xlnx,num-monitor-slots = <0x01>;
			compatible = "xlnx,axi-perf-monitor";
			xlnx,num-of-counters = <0x08>;
			reg = <0x00 0xffa00000 0x00 0x10000>;
			phandle = <0x56>;
			xlnx,metrics-sample-count-width = <0x20>;
			xlnx,enable-event-log = <0x01>;
		};

		dma-controller@ffad0000 {
			power-domains = <0x12 0x2b>;
			clock-names = "clk_main\0clk_apb";
			interrupts = <0x00 0x52 0x04>;
			clocks = <0x04 0x44 0x04 0x1f>;
			interrupt-parent = <0x05>;
			xlnx,bus-width = <0x40>;
			compatible = "xlnx,zynqmp-dma-1.0";
			status = "okay";
			reg = <0x00 0xffad0000 0x00 0x1000>;
			phandle = <0x49>;
			#dma-cells = <0x01>;
		};

		gpu@fd4b0000 {
			power-domains = <0x12 0x3a>;
			xlnx,tz-nonsecure = <0x01>;
			clock-names = "bus\0core";
			interrupts = <0x00 0x84 0x04 0x00 0x84 0x04 0x00 0x84 0x04 0x00 0x84 0x04 0x00 0x84 0x04 0x00 0x84 0x04>;
			clocks = <0x04 0x18 0x04 0x19>;
			interrupt-parent = <0x05>;
			compatible = "xlnx,zynqmp-mali\0arm,mali-400";
			status = "okay";
			interrupt-names = "gp\0gpmmu\0pp0\0ppmmu0\0pp1\0ppmmu1";
			reg = <0x00 0xfd4b0000 0x00 0x10000>;
			phandle = <0x43>;
		};

		dp-aud@fd4ac000 {
			compatible = "xlnx,zynqmp-dpaud-setting\0syscon";
			reg = <0x00 0xfd4ac000 0x00 0x1000>;
			phandle = <0x18>;
		};

		serial@ff000000 {
			power-domains = <0x12 0x21>;
			clock-names = "uart_clk\0pclk";
			u-boot,dm-pre-reloc;
			bootph-all;
			cts-override;
			interrupts = <0x00 0x15 0x04>;
			clocks = <0x04 0x38 0x04 0x1f>;
			interrupt-parent = <0x05>;
			device_type = "serial";
			port-number = <0x00>;
			compatible = "xlnx,zynqmp-uart\0cdns,uart-r1p12";
			status = "okay";
			reg = <0x00 0xff000000 0x00 0x1000>;
			phandle = <0x66>;
		};

		i2c@ff030000 {
			power-domains = <0x12 0x26>;
			#address-cells = <0x01>;
			interrupts = <0x00 0x12 0x04>;
			clocks = <0x04 0x3e>;
			#size-cells = <0x00>;
			interrupt-parent = <0x05>;
			clock-frequency = <0x61a80>;
			compatible = "cdns,i2c-r1p14";
			status = "okay";
			reg = <0x00 0xff030000 0x00 0x1000>;
			phandle = <0x54>;
		};

		watchdog@fd4d0000 {
			interrupts = <0x00 0x71 0x01>;
			clocks = <0x04 0x4b>;
			interrupt-parent = <0x05>;
			timeout-sec = <0x3c>;
			reset-on-timeout;
			compatible = "cdns,wdt-r1p2";
			status = "disabled";
			reg = <0x00 0xfd4d0000 0x00 0x1000>;
			phandle = <0x6c>;
		};

		dma-controller@fd530000 {
			power-domains = <0x12 0x2a>;
			iommus = <0x13 0x14eb>;
			clock-names = "clk_main\0clk_apb";
			interrupts = <0x00 0x7f 0x04>;
			clocks = <0x04 0x13 0x04 0x1f>;
			interrupt-parent = <0x05>;
			xlnx,bus-width = <0x80>;
			compatible = "xlnx,zynqmp-dma-1.0";
			status = "okay";
			reg = <0x00 0xfd530000 0x00 0x1000>;
			phandle = <0x3e>;
			#dma-cells = <0x01>;
		};

		phy@fd400000 {
			reg-names = "serdes\0siou";
			#phy-cells = <0x04>;
			compatible = "xlnx,zynqmp-psgtr-v1.1";
			status = "okay";
			reg = <0x00 0xfd400000 0x00 0x40000 0x00 0xfd3d0000 0x00 0x1000>;
			phandle = <0x5b>;
		};

		dma-controller@fd570000 {
			power-domains = <0x12 0x2a>;
			iommus = <0x13 0x14ef>;
			clock-names = "clk_main\0clk_apb";
			interrupts = <0x00 0x83 0x04>;
			clocks = <0x04 0x13 0x04 0x1f>;
			interrupt-parent = <0x05>;
			xlnx,bus-width = <0x80>;
			compatible = "xlnx,zynqmp-dma-1.0";
			status = "okay";
			reg = <0x00 0xfd570000 0x00 0x1000>;
			phandle = <0x42>;
			#dma-cells = <0x01>;
		};

		spi@ff0f0000 {
			power-domains = <0x12 0x2d>;
			iommus = <0x13 0x873>;
			#address-cells = <0x01>;
			num-cs = <0x01>;
			clock-names = "ref_clk\0pclk";
			bootph-all;
			interrupts = <0x00 0x0f 0x04>;
			clocks = <0x04 0x35 0x04 0x1f>;
			#size-cells = <0x00>;
			interrupt-parent = <0x05>;
			compatible = "xlnx,zynqmp-qspi-1.0";
			status = "disabled";
			reg = <0x00 0xff0f0000 0x00 0x1000 0x00 0xc0000000 0x00 0x8000000>;
			phandle = <0x5a>;
		};

		timer@ff130000 {
			power-domains = <0x12 0x1a>;
			timer-width = <0x20>;
			interrupts = <0x00 0x2a 0x04 0x00 0x2b 0x04 0x00 0x2c 0x04>;
			clocks = <0x04 0x1f>;
			interrupt-parent = <0x05>;
			compatible = "cdns,ttc";
			status = "disabled";
			reg = <0x00 0xff130000 0x00 0x1000>;
			phandle = <0x64>;
		};

		spi@ff040000 {
			power-domains = <0x12 0x23>;
			#address-cells = <0x01>;
			num-cs = <0x03>;
			is-decoded-cs = <0x00>;
			clock-names = "ref_clk\0pclk";
			interrupts = <0x00 0x13 0x04>;
			clocks = <0x04 0x3a 0x04 0x1f>;
			#size-cells = <0x00>;
			interrupt-parent = <0x05>;
			compatible = "cdns,spi-r1p6";
			status = "okay";
			reg = <0x00 0xff040000 0x00 0x1000>;
			phandle = <0x60>;
		};

		ethernet@ff0d0000 {
			power-domains = <0x12 0x1f>;
			iommus = <0x13 0x876>;
			#address-cells = <0x01>;
			clock-names = "pclk\0hclk\0tx_clk\0rx_clk\0tsu_clk";
			assigned-clocks = <0x04 0x2c>;
			resets = <0x11 0x1f>;
			interrupts = <0x00 0x3d 0x04 0x00 0x3d 0x04>;
			clocks = <0x04 0x1f 0x04 0x6a 0x04 0x2f 0x04 0x33 0x04 0x2c>;
			#size-cells = <0x00>;
			interrupt-parent = <0x05>;
			compatible = "xlnx,zynqmp-gem\0cdns,gem";
			status = "disabled";
			reg = <0x00 0xff0d0000 0x00 0x1000>;
			phandle = <0x50>;
			reset-names = "gem2_rst";
		};

		can@ff070000 {
			power-domains = <0x12 0x30>;
			clock-names = "can_clk\0pclk";
			resets = <0x11 0x29>;
			interrupts = <0x00 0x18 0x04>;
			clocks = <0x04 0x40 0x04 0x1f>;
			interrupt-parent = <0x05>;
			compatible = "xlnx,zynq-can-1.0";
			status = "disabled";
			tx-fifo-depth = <0x40>;
			rx-fifo-depth = <0x40>;
			reg = <0x00 0xff070000 0x00 0x1000>;
			phandle = <0x39>;
		};

		dma-controller@ffaa0000 {
			power-domains = <0x12 0x2b>;
			clock-names = "clk_main\0clk_apb";
			interrupts = <0x00 0x4f 0x04>;
			clocks = <0x04 0x44 0x04 0x1f>;
			interrupt-parent = <0x05>;
			xlnx,bus-width = <0x40>;
			compatible = "xlnx,zynqmp-dma-1.0";
			status = "okay";
			reg = <0x00 0xffaa0000 0x00 0x1000>;
			phandle = <0x46>;
			#dma-cells = <0x01>;
		};

		perf-monitor@ffa10000 {
			xlnx,metric-count-width = <0x20>;
			xlnx,have-sampled-metric-cnt = <0x01>;
			xlnx,enable-trace = <0x00>;
			xlnx,global-count-width = <0x20>;
			xlnx,enable-event-count = <0x01>;
			interrupts = <0x00 0x19 0x04>;
			clocks = <0x04 0x1f>;
			xlnx,enable-profile = <0x00>;
			xlnx,metric-count-scale = <0x01>;
			interrupt-parent = <0x05>;
			xlnx,num-monitor-slots = <0x01>;
			compatible = "xlnx,axi-perf-monitor";
			xlnx,num-of-counters = <0x08>;
			reg = <0x00 0xffa10000 0x00 0x10000>;
			phandle = <0x59>;
			xlnx,metrics-sample-count-width = <0x20>;
			xlnx,enable-event-log = <0x01>;
		};

		mmc@ff160000 {
			power-domains = <0x12 0x27>;
			iommus = <0x13 0x870>;
			clock-output-names = "clk_out_sd0\0clk_in_sd0";
			clock-names = "clk_xin\0clk_ahb";
			assigned-clocks = <0x04 0x36>;
			bootph-all;
			resets = <0x11 0x26>;
			interrupts = <0x00 0x30 0x04>;
			clocks = <0x04 0x36 0x04 0x1f>;
			#clock-cells = <0x01>;
			interrupt-parent = <0x05>;
			compatible = "xlnx,zynqmp-8.9a\0arasan,sdhci-8.9a";
			status = "disabled";
			reg = <0x00 0xff160000 0x00 0x1000>;
			phandle = <0x5e>;
		};

		dma-controller@ffae0000 {
			power-domains = <0x12 0x2b>;
			clock-names = "clk_main\0clk_apb";
			interrupts = <0x00 0x53 0x04>;
			clocks = <0x04 0x44 0x04 0x1f>;
			interrupt-parent = <0x05>;
			xlnx,bus-width = <0x40>;
			compatible = "xlnx,zynqmp-dma-1.0";
			status = "okay";
			reg = <0x00 0xffae0000 0x00 0x1000>;
			phandle = <0x4a>;
		};

		perf-monitor@fd490000 {
			xlnx,metric-count-width = <0x20>;
			xlnx,have-sampled-metric-cnt = <0x01>;
			xlnx,enable-trace = <0x00>;
			xlnx,global-count-width = <0x20>;
			xlnx,enable-event-count = <0x01>;
			interrupts = <0x00 0x7b 0x04>;
			clocks = <0x04 0x1c>;
			xlnx,enable-profile = <0x00>;
			xlnx,metric-count-scale = <0x01>;
			interrupt-parent = <0x05>;
			xlnx,num-monitor-slots = <0x01>;
			compatible = "xlnx,axi-perf-monitor";
			xlnx,num-of-counters = <0x08>;
			reg = <0x00 0xfd490000 0x00 0x10000>;
			phandle = <0x58>;
			xlnx,metrics-sample-count-width = <0x20>;
			xlnx,enable-event-log = <0x00>;
		};

		serial@ff010000 {
			power-domains = <0x12 0x22>;
			clock-names = "uart_clk\0pclk";
			u-boot,dm-pre-reloc;
			bootph-all;
			cts-override;
			interrupts = <0x00 0x16 0x04>;
			clocks = <0x04 0x39 0x04 0x1f>;
			interrupt-parent = <0x05>;
			device_type = "serial";
			port-number = <0x01>;
			compatible = "xlnx,zynqmp-uart\0cdns,uart-r1p12";
			status = "okay";
			reg = <0x00 0xff010000 0x00 0x1000>;
			phandle = <0x67>;
		};

		zyxclmm_drm {
			memory-region = <0x1d>;
			interrupts = <0x00 0x89 0x04 0x00 0x90 0x04 0x00 0x91 0x04 0x00 0x92 0x04 0x00 0x93 0x04 0x00 0x94 0x04 0x00 0x95 0x04 0x00 0x96 0x04>;
			interrupt-parent = <0x05>;
			compatible = "xlnx,zocl";
		};

		dma-controller@fd500000 {
			power-domains = <0x12 0x2a>;
			iommus = <0x13 0x14e8>;
			clock-names = "clk_main\0clk_apb";
			interrupts = <0x00 0x7c 0x04>;
			clocks = <0x04 0x13 0x04 0x1f>;
			interrupt-parent = <0x05>;
			xlnx,bus-width = <0x80>;
			compatible = "xlnx,zynqmp-dma-1.0";
			status = "okay";
			reg = <0x00 0xfd500000 0x00 0x1000>;
			phandle = <0x3b>;
			#dma-cells = <0x01>;
		};

		ahci@fd0c0000 {
			power-domains = <0x12 0x1c>;
			resets = <0x11 0x10>;
			interrupts = <0x00 0x85 0x04>;
			clocks = <0x04 0x16>;
			interrupt-parent = <0x05>;
			xlnx,tz-nonsecure-sata0 = <0x00>;
			compatible = "ceva,ahci-1v84";
			status = "okay";
			reg = <0x00 0xfd0c0000 0x00 0x2000>;
			phandle = <0x5d>;
			xlnx,tz-nonsecure-sata1 = <0x00>;
		};

		cci@fd6e0000 {
			#address-cells = <0x01>;
			#size-cells = <0x01>;
			compatible = "arm,cci-400";
			ranges = <0x00 0x00 0xfd6e0000 0x10000>;
			status = "okay";
			reg = <0x00 0xfd6e0000 0x00 0x9000>;
			phandle = <0x3a>;

			pmu@9000 {
				interrupts = <0x00 0x7b 0x04 0x00 0x7b 0x04 0x00 0x7b 0x04 0x00 0x7b 0x04 0x00 0x7b 0x04>;
				interrupt-parent = <0x05>;
				compatible = "arm,cci-400-pmu,r1";
				reg = <0x9000 0x5000>;
			};
		};

		dma-controller@fd540000 {
			power-domains = <0x12 0x2a>;
			iommus = <0x13 0x14ec>;
			clock-names = "clk_main\0clk_apb";
			interrupts = <0x00 0x80 0x04>;
			clocks = <0x04 0x13 0x04 0x1f>;
			interrupt-parent = <0x05>;
			xlnx,bus-width = <0x80>;
			compatible = "xlnx,zynqmp-dma-1.0";
			status = "okay";
			reg = <0x00 0xfd540000 0x00 0x1000>;
			phandle = <0x3f>;
			#dma-cells = <0x01>;
		};

		pcie@fd0e0000 {
			power-domains = <0x12 0x3b>;
			iommus = <0x13 0x4d0>;
			#address-cells = <0x03>;
			bus-range = <0x00 0xff>;
			reg-names = "breg\0pcireg\0cfg";
			interrupts = <0x00 0x76 0x04 0x00 0x75 0x04 0x00 0x74 0x04 0x00 0x73 0x04 0x00 0x72 0x04>;
			clocks = <0x04 0x17>;
			interrupt-map = <0x00 0x00 0x00 0x01 0x16 0x01 0x00 0x00 0x00 0x02 0x16 0x02 0x00 0x00 0x00 0x03 0x16 0x03 0x00 0x00 0x00 0x04 0x16 0x04>;
			#size-cells = <0x02>;
			interrupt-parent = <0x05>;
			msi-controller;
			device_type = "pci";
			interrupt-map-mask = <0x00 0x00 0x00 0x07>;
			compatible = "xlnx,nwl-pcie-2.11";
			ranges = <0x2000000 0x00 0xe0000000 0x00 0xe0000000 0x00 0x10000000 0x43000000 0x06 0x00 0x06 0x00 0x02 0x00>;
			#interrupt-cells = <0x01>;
			status = "disabled";
			interrupt-names = "misc\0dummy\0intx\0msi1\0msi0";
			reg = <0x00 0xfd0e0000 0x00 0x1000 0x00 0xfd480000 0x00 0x1000 0x80 0x00 0x00 0x10000000>;
			phandle = <0x15>;
			msi-parent = <0x15>;

			legacy-interrupt-controller {
				#address-cells = <0x00>;
				#interrupt-cells = <0x01>;
				phandle = <0x16>;
				interrupt-controller;
			};
		};
	};

	udmabuf0 {
		device-name = "udmabuf0";
		dma-coherent;
		memory-region = <0x1e>;
		compatible = "ikwzm,u-dma-buf";
		size = <0x01 0x00>;
		phandle = <0x77>;
		dma-mask = <0x28>;
	};
};
